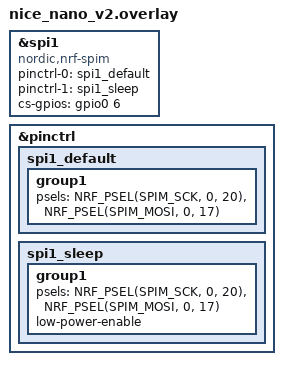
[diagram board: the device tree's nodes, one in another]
/*
 * Copyright (c) 2023 The ZMK Contributors
 *
 * SPDX-License-Identifier: MIT
 */

#include <dt-bindings/gpio/gpio.h>
#include <dt-bindings/pinctrl/nrf-pinctrl.h>

&spi1 {
    status = "okay";
    compatible = "nordic,nrf-spim";
    pinctrl-0 = <&spi1_default>;
    pinctrl-1 = <&spi1_sleep>;
    pinctrl-names = "default", "sleep";
    cs-gpios = <&gpio0 6 GPIO_ACTIVE_HIGH>; // D1 = P0.06
};

&pinctrl {
    spi1_default: spi1_default {
        group1 {
            psels = <NRF_PSEL(SPIM_SCK, 0, 20)>,   // D2
                <NRF_PSEL(SPIM_MOSI, 0, 17)>;      // D3
        };
    };

    spi1_sleep: spi1_sleep {
        group1 {
            psels = <NRF_PSEL(SPIM_SCK, 0, 20)>,   // D2
                <NRF_PSEL(SPIM_MOSI, 0, 17)>;      // D3
            low-power-enable;
        };
    };
};

nice_view_spi: &spi1 {};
